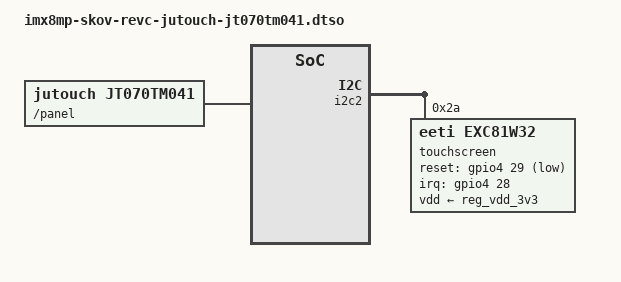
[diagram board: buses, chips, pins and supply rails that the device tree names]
// SPDX-License-Identifier: (GPL-2.0 OR MIT)

/dts-v1/;
/plugin/;

#include <dt-bindings/interrupt-controller/irq.h>
#include <dt-bindings/gpio/gpio.h>

&{/} {
	model = "SKOV IMX8MP CPU revC - JuTouch JT070TM041";
	compatible = "skov,imx8mp-skov-revc-jutouch-jt070tm041", "fsl,imx8mp";
};

&{/panel} {
	compatible = "jutouch,jt070tm041";
};

&i2c2 {
	#address-cells = <1>;
	#size-cells = <0>;

	touchscreen@2a {
		compatible = "eeti,exc81w32", "eeti,exc80h84";
		reg = <0x2a>;
		pinctrl-names = "default";
		pinctrl-0 = <&pinctrl_touchscreen>;
		interrupts-extended = <&gpio4 28 IRQ_TYPE_LEVEL_LOW>;
		reset-gpios = <&gpio4 29 GPIO_ACTIVE_LOW>;
		touchscreen-size-x = <1024>;
		touchscreen-size-y = <600>;
		vdd-supply = <&reg_vdd_3v3>;
	};
};

&lvds_bridge {
	/* IMX8MP_VIDEO_PLL1 = IMX8MP_CLK_MEDIA_DISP2_PIX * 7 */
	assigned-clock-rates = <0>, <358400000>;
};
